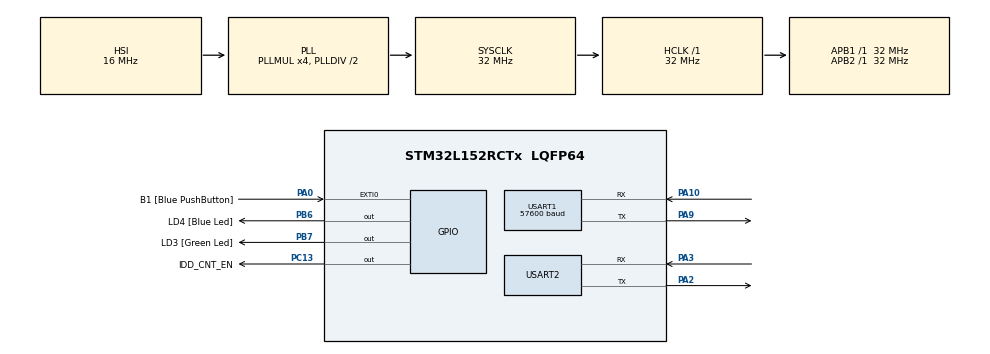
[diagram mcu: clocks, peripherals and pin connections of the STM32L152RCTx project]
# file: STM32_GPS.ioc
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Mcu.Family=STM32L1
Mcu.Name=STM32L152RCTx
Mcu.Package=LQFP64
NVIC.PriorityGroup=NVIC_PRIORITYGROUP_0
NVIC.USART1_IRQn=true\:0\:0\:false\:false\:true\:true\:true
NVIC.USART2_IRQn=true\:0\:0\:false\:false\:true\:true\:true
PA0-WKUP1.GPIO_Label=B1 [Blue PushButton]
PA0-WKUP1.GPIO_ModeDefaultEXTI=GPIO_MODE_EVT_RISING
PA0-WKUP1.GPIO_PuPd=GPIO_NOPULL
PA0-WKUP1.Signal=GPXTI0
PA10.Mode=Asynchronous
PA10.Signal=USART1_RX
PA2.Mode=Asynchronous
PA2.Signal=USART2_TX
PA3.Mode=Asynchronous
PA3.Signal=USART2_RX
PA9.Mode=Asynchronous
PA9.Signal=USART1_TX
PB6.GPIO_Label=LD4 [Blue Led]
PB6.GPIO_ModeDefaultOutputPP=GPIO_MODE_OUTPUT_PP
PB6.GPIO_PuPd=GPIO_NOPULL
PB6.GPIO_Speed=GPIO_SPEED_FREQ_LOW
PB6.Signal=GPIO_Output
PB7.GPIO_Label=LD3 [Green Led]
PB7.GPIO_ModeDefaultOutputPP=GPIO_MODE_OUTPUT_PP
PB7.GPIO_PuPd=GPIO_NOPULL
PB7.GPIO_Speed=GPIO_SPEED_FREQ_LOW
PB7.Signal=GPIO_Output
PC13-WKUP2.GPIO_Label=IDD_CNT_EN
PC13-WKUP2.Signal=GPIO_Output
ProjectManager.HeapSize=0x200
ProjectManager.StackSize=0x400
ProjectManager.TargetToolchain=STM32CubeIDE
RCC.48MHZClocksFreq_Value=32000000
RCC.AHBFreq_Value=32000000
RCC.APB1Freq_Value=32000000
RCC.APB1TimFreq_Value=32000000
RCC.APB2Freq_Value=32000000
RCC.APB2TimFreq_Value=32000000
RCC.HCLKFreq_Value=32000000
RCC.HSE_VALUE=8000000
RCC.HSI_VALUE=16000000
RCC.MSI_VALUE=2097000
RCC.PLLMUL=RCC_PLL_MUL4
RCC.RTCClockSelectionVirtual=RCC_RTCCLKSOURCE_LSE
RCC.SYSCLKFreq_VALUE=32000000
RCC.SYSCLKSource=RCC_SYSCLKSOURCE_PLLCLK
RCC.USBOutput=48000000
RCC.VCOOutputFreq_Value=64000000
USART1.BaudRate=57600
USART1.VirtualMode=VM_ASYNC
USART2.VirtualMode=VM_ASYNC
board=STM32L152C-DISCO

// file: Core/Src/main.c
/* USER CODE BEGIN Header */
/**
  ******************************************************************************
  * @file           : main.c
  * @brief          : Main program body
  ******************************************************************************
  * @attention
  *
  * <h2><center>&copy; Copyright (c) 2019 STMicroelectronics.
  * All rights reserved.</center></h2>
  *
  * This software component is licensed by ST under BSD 3-Clause license,
  * the "License"; You may not use this file except in compliance with the
  * License. You may obtain a copy of the License at:
  *                        opensource.org/licenses/BSD-3-Clause
  *
  ******************************************************************************
  */
/* USER CODE END Header */

#include "main.h"
#include "usart.h"
#include "gpio.h"
#include "gps.h"

/* USER CODE BEGIN PV */
struct gps_state gps_handle;
uint8_t recv_char;
/* USER CODE END PV */

void SystemClock_Config(void);

int main(void)
{

  /* MCU Configuration--------------------------------------------------------*/

  /* Reset of all peripherals, Initializes the Flash interface and the Systick. */
  HAL_Init();

  /* Configure the system clock */
  SystemClock_Config();

  /* Initialize all configured peripherals */
  MX_GPIO_Init();
  MX_USART1_UART_Init();
  MX_USART2_UART_Init();
  /* USER CODE BEGIN 2 */
  //configureUblox();
 // gps_handle = gps_init(&huart1);
  //HAL_UART_Receive_IT(&huart1, &recv_char, 1);
	HAL_GPIO_WritePin(GPIOB, GPIO_PIN_6, GPIO_PIN_SET);
	HAL_Delay(1000);
	HAL_GPIO_WritePin(GPIOB,GPIO_PIN_6, GPIO_PIN_RESET);

  /* USER CODE END 2 */

  /* Infinite loop */
  while (1)
  {

  }
}

void SystemClock_Config(void)
{
  RCC_OscInitTypeDef RCC_OscInitStruct = {0};
  RCC_ClkInitTypeDef RCC_ClkInitStruct = {0};

  /** Configure the main internal regulator output voltage
  */
  __HAL_PWR_VOLTAGESCALING_CONFIG(PWR_REGULATOR_VOLTAGE_SCALE1);
  /** Initializes the CPU, AHB and APB busses clocks
  */
  RCC_OscInitStruct.OscillatorType = RCC_OSCILLATORTYPE_HSI;
  RCC_OscInitStruct.HSIState = RCC_HSI_ON;
  RCC_OscInitStruct.HSICalibrationValue = RCC_HSICALIBRATION_DEFAULT;
  RCC_OscInitStruct.PLL.PLLState = RCC_PLL_ON;
  RCC_OscInitStruct.PLL.PLLSource = RCC_PLLSOURCE_HSI;
  RCC_OscInitStruct.PLL.PLLMUL = RCC_PLL_MUL4;
  RCC_OscInitStruct.PLL.PLLDIV = RCC_PLL_DIV2;
  if (HAL_RCC_OscConfig(&RCC_OscInitStruct) != HAL_OK)
  {
    Error_Handler();
  }
  /** Initializes the CPU, AHB and APB busses clocks
  */
  RCC_ClkInitStruct.ClockType = RCC_CLOCKTYPE_HCLK|RCC_CLOCKTYPE_SYSCLK
                              |RCC_CLOCKTYPE_PCLK1|RCC_CLOCKTYPE_PCLK2;
  RCC_ClkInitStruct.SYSCLKSource = RCC_SYSCLKSOURCE_PLLCLK;
  RCC_ClkInitStruct.AHBCLKDivider = RCC_SYSCLK_DIV1;
  RCC_ClkInitStruct.APB1CLKDivider = RCC_HCLK_DIV1;
  RCC_ClkInitStruct.APB2CLKDivider = RCC_HCLK_DIV1;

  if (HAL_RCC_ClockConfig(&RCC_ClkInitStruct, FLASH_LATENCY_1) != HAL_OK)
  {
    Error_Handler();
  }
}

/* USER CODE BEGIN 4 */
void HAL_UART_RxCpltCallback(UART_HandleTypeDef * uart) {
	if (uart == &huart1) {
		receiveChar(&gps_handle, recv_char);
		HAL_UART_Receive_IT(&huart1, &recv_char, 1);
	}
}
/* USER CODE END 4 */

void Error_Handler(void)
{
}

/************************ (C) COPYRIGHT STMicroelectronics *****END OF FILE****/
